AUTOSAR XML (schema 00044)
package /E40_Platform_System_SystemPackage/Components
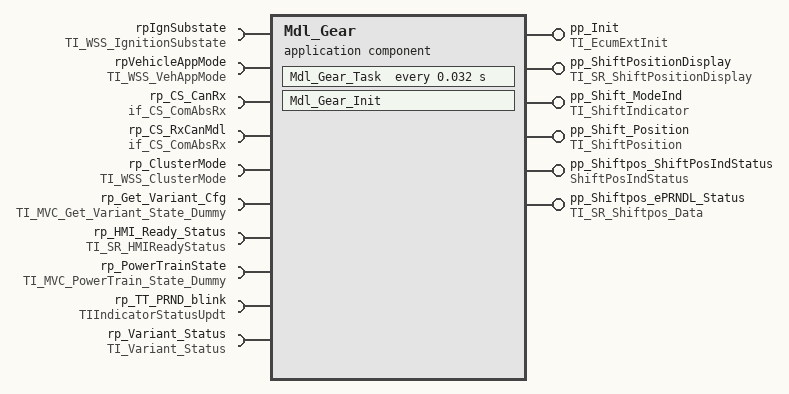
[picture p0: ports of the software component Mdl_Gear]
  application sw component type Mdl_Gear
    6 x provide port:
      pp_Init: server-com-spec{operation=Init, queue-length=1}, provided-interface=TI_EcumExtInit
      pp_ShiftPositionDisplay: nonqueued-sender-com-spec{data-element=ShiftPositionDisplay, init-value=constant-reference=Mdl_GearShiftPositionDisplayValue0}, provided-interface=TI_SR_ShiftPositionDisplay
      pp_Shift_ModeInd: nonqueued-sender-com-spec{data-element=ShiftModeIndicator, init-value=constant-reference=Mdl_GearShiftModeIndicatorValue0}, provided-interface=TI_ShiftIndicator
      pp_Shift_Position: nonqueued-sender-com-spec{data-element=ShiftPosition, init-value=constant-reference=Mdl_GearShiftPositionValue0}, provided-interface=TI_ShiftPosition
      pp_Shiftpos_ShiftPosIndStatus: nonqueued-sender-com-spec{data-element=ShiftPosIndStatusData, init-value=constant-reference=Mdl_GearShiftPosIndStatusDataValue0}, provided-interface=ShiftPosIndStatus
      pp_Shiftpos_ePRNDL_Status: nonqueued-sender-com-spec{data-element=ShiftPos_Data, init-value=constant-reference=Mdl_GearShiftPos_DataValue0}, provided-interface=TI_SR_Shiftpos_Data
    10 x require port:
      rpIgnSubstate: nonqueued-receiver-com-spec{data-element=IgnitionSubstate, init-value=constant-reference=Mdl_GearIgnitionSubstateValue0}, required-interface=TI_WSS_IgnitionSubstate
      rpVehicleAppMode: nonqueued-receiver-com-spec{data-element=WSSCurrentVehicleState, init-value=constant-reference=Mdl_GearWSSCurrentVehicleStateValue0}, required-interface=TI_WSS_VehAppMode
      rp_CS_CanRx: required-interface=if_CS_ComAbsRx
        required-com-specs:
          RxCan_GetSignalValue
          RxCan_GetSignalValueU8Arr
          RxCan_SetSignalInitValue
          RxCan_SetSignalInitValueU8Arr
          RxCan_SignalClearJustRcvdStatus
          RxCan_SignalGetJustRcvdStatus
          RxCan_SignalInvalidProcessingControl
          RxCan_SignalMissingProcessingControl
          RxCan_SignalNRProcessingControl
      rp_CS_RxCanMdl: required-interface=if_CS_ComAbsRx
        required-com-specs:
          RxCan_GetSignalValue
          RxCan_GetSignalValueU8Arr
          RxCan_SetSignalInitValue
          RxCan_SetSignalInitValueU8Arr
          RxCan_SignalClearJustRcvdStatus
          RxCan_SignalGetJustRcvdStatus
          RxCan_SignalInvalidProcessingControl
          RxCan_SignalMissingProcessingControl
          RxCan_SignalNRProcessingControl
      rp_ClusterMode: nonqueued-receiver-com-spec{data-element=WSSCurrentClusterMode, init-value=constant-reference=Mdl_GearWSSCurrentClusterModeValue0}, required-interface=TI_WSS_ClusterMode
      rp_Get_Variant_Cfg: client-com-spec=Get_Variant_Config_State, required-interface=TI_MVC_Get_Variant_State_Dummy
      rp_HMI_Ready_Status: nonqueued-receiver-com-spec{data-element=HMI_ReadyStatus, init-value=constant-reference=Mdl_GearHMI_ReadyStatusValue0}, required-interface=TI_SR_HMIReadyStatus
      rp_PowerTrainState: nonqueued-receiver-com-spec{data-element=PowerTrain_Flag, init-value=constant-reference=Mdl_GearPowerTrain_FlagValue0}, required-interface=TI_MVC_PowerTrain_State_Dummy
      rp_TT_PRND_blink: nonqueued-receiver-com-spec{data-element=TIUpdateIndicatorStatus, init-value=constant-reference=Mdl_GearTIUpdateIndicatorStatusValue0}, required-interface=TIIndicatorStatusUpdt
      rp_Variant_Status: client-com-spec=GetVariant_Status, required-interface=TI_Variant_Status
    behavior IB_Mdl_Gear
      operation invoked event OIE_pp_Init_Mdl_Gear_InitTrigByInit: start-on-event=Mdl_Gear_Init, operation=pp_Init.Init
      timing event TEMdl_Gear_Task: start-on-event=Mdl_Gear_Task, period=0.032
      port-api-options:
        enable-take-address=false, indirect-api=false, port=pp_Init
        enable-take-address=false, indirect-api=false, port=pp_ShiftPositionDisplay
        enable-take-address=false, indirect-api=false, port=pp_Shift_ModeInd
        enable-take-address=false, indirect-api=false, port=pp_Shift_Position
        enable-take-address=false, indirect-api=false, port=pp_Shiftpos_ShiftPosIndStatus
        enable-take-address=false, indirect-api=false, port=pp_Shiftpos_ePRNDL_Status
        enable-take-address=false, indirect-api=false, port=rpIgnSubstate
        enable-take-address=false, indirect-api=false, port=rpVehicleAppMode
        enable-take-address=false, indirect-api=false, port=rp_CS_CanRx
        enable-take-address=false, indirect-api=false, port=rp_CS_RxCanMdl
        enable-take-address=false, indirect-api=false, port=rp_ClusterMode
        enable-take-address=false, indirect-api=false, port=rp_Get_Variant_Cfg
        enable-take-address=false, indirect-api=false, port=rp_HMI_Ready_Status
        enable-take-address=false, indirect-api=false, port=rp_PowerTrainState
        enable-take-address=false, indirect-api=false, port=rp_TT_PRND_blink
        enable-take-address=false, indirect-api=false, port=rp_Variant_Status
      runnable Mdl_Gear_Init: can-be-invoked-concurrently=true
      runnable Mdl_Gear_Task: can-be-invoked-concurrently=true
        data-receive-point-by-arguments:
          6 x access:
            DRA_rpIgnSubstate_IgnitionSubstate: accessed-variable=rpIgnSubstate.IgnitionSubstate
            DRA_rpVehicleAppMode_WSSCurrentVehicleState: accessed-variable=rpVehicleAppMode.WSSCurrentVehicleState
            DRA_rp_ClusterMode_WSSCurrentClusterMode: accessed-variable=rp_ClusterMode.WSSCurrentClusterMode
            DRA_rp_HMI_Ready_Status_HMI_ReadyStatus: accessed-variable=rp_HMI_Ready_Status.HMI_ReadyStatus
            DRA_rp_PowerTrainState_PowerTrain_Flag: accessed-variable=rp_PowerTrainState.PowerTrain_Flag
            DRA_rp_TT_PRND_blink_TIUpdateIndicatorStatus: accessed-variable=rp_TT_PRND_blink.TIUpdateIndicatorStatus
        data-send-points:
          5 x access:
            DWA_pp_ShiftPositionDisplay_ShiftPositionDisplay: accessed-variable=pp_ShiftPositionDisplay.ShiftPositionDisplay
            DWA_pp_Shift_ModeInd_ShiftModeIndicator: accessed-variable=pp_Shift_ModeInd.ShiftModeIndicator
            DWA_pp_Shift_Position_ShiftPosition: accessed-variable=pp_Shift_Position.ShiftPosition
            DWA_pp_Shiftpos_ShiftPosIndStatus_ShiftPosIndStatusData: accessed-variable=pp_Shiftpos_ShiftPosIndStatus.ShiftPosIndStatusData
            DWA_pp_Shiftpos_ePRNDL_Status_ShiftPos_Data: accessed-variable=pp_Shiftpos_ePRNDL_Status.ShiftPos_Data
        20 x sync call:
          OA_rp_CS_CanRx_RxCan_GetSignalValueU8Arr: operation=rp_CS_CanRx.RxCan_GetSignalValueU8Arr
          OA_rp_CS_CanRx_RxCan_SetSignalInitValue: operation=rp_CS_CanRx.RxCan_SetSignalInitValue
          OA_rp_CS_CanRx_RxCan_SetSignalInitValueU8Arr: operation=rp_CS_CanRx.RxCan_SetSignalInitValueU8Arr
          OA_rp_CS_CanRx_RxCan_SignalInvalidProcessingControl: operation=rp_CS_CanRx.RxCan_SignalInvalidProcessingControl
          OA_rp_CS_CanRx_RxCan_SignalMissingProcessingControl: operation=rp_CS_CanRx.RxCan_SignalMissingProcessingControl
          OA_rp_CS_CanRx_RxCan_SignalNRProcessingControl: operation=rp_CS_CanRx.RxCan_SignalNRProcessingControl
          OA_rp_CS_CanRx_RxCan_SignalGetJustRcvdStatus: operation=rp_CS_CanRx.RxCan_SignalGetJustRcvdStatus
          OA_rp_CS_CanRx_RxCan_SignalClearJustRcvdStatus: operation=rp_CS_CanRx.RxCan_SignalClearJustRcvdStatus
          OA_rp_CS_CanRx_RxCan_GetSignalValue: operation=rp_CS_CanRx.RxCan_GetSignalValue
          OA_rp_CS_RxCanMdl_RxCan_GetSignalValueU8Arr: operation=rp_CS_RxCanMdl.RxCan_GetSignalValueU8Arr
          OA_rp_CS_RxCanMdl_RxCan_SetSignalInitValue: operation=rp_CS_RxCanMdl.RxCan_SetSignalInitValue
          OA_rp_CS_RxCanMdl_RxCan_SetSignalInitValueU8Arr: operation=rp_CS_RxCanMdl.RxCan_SetSignalInitValueU8Arr
          OA_rp_CS_RxCanMdl_RxCan_SignalInvalidProcessingControl: operation=rp_CS_RxCanMdl.RxCan_SignalInvalidProcessingControl
          OA_rp_CS_RxCanMdl_RxCan_SignalMissingProcessingControl: operation=rp_CS_RxCanMdl.RxCan_SignalMissingProcessingControl
          OA_rp_CS_RxCanMdl_RxCan_SignalNRProcessingControl: operation=rp_CS_RxCanMdl.RxCan_SignalNRProcessingControl
          OA_rp_CS_RxCanMdl_RxCan_SignalGetJustRcvdStatus: operation=rp_CS_RxCanMdl.RxCan_SignalGetJustRcvdStatus
          OA_rp_CS_RxCanMdl_RxCan_SignalClearJustRcvdStatus: operation=rp_CS_RxCanMdl.RxCan_SignalClearJustRcvdStatus
          OA_rp_CS_RxCanMdl_RxCan_GetSignalValue: operation=rp_CS_RxCanMdl.RxCan_GetSignalValue
          OA_rp_Get_Variant_Cfg_Get_Variant_Config_State: operation=rp_Get_Variant_Cfg.Get_Variant_Config_State
          OA_rp_Variant_Status_GetVariant_Status: operation=rp_Variant_Status.GetVariant_Status
  swc implementation IMPL_Mdl_Gear: behavior=IB_Mdl_Gear
